# SWM330 register map
File version: 1.0
SWM330 Microcontroller registers
CPU: CM0 r1p0, little endian, 2 interrupt priority bits
Registers are 32-bit, read-write, no defined reset value unless marked. A register's access mark holds for its fields unless they carry their own. Offsets are from the block's base; lines under a group give offsets from that group; [hi:lo] are bit positions; {n}, {i} and the like mark numbered series; 'fields as' and 'values as' point back to an identical list; <NAME> marks a mode.

## Memory map
0x40000000 SYS size 0xA5840 — Registers group
0x40000800 DMA size 0x50 — Registers group
0x40001000 SDIO size 0x40 — Registers group
0x40001800 LCD size 0x10C — Registers group
0x40002000 CRC size 0x10 — Registers group
0x40002800 SRA size 0x48 — Registers group
0x40003000 DMA2D size 0x4C — Registers group
0x40003900 DVP size 0x58 — Registers group
0x40004000 JPEG size 0x400 — Registers group
0x40005000 RDMA size 0x1C — Registers group
0x40040000 GPIOA size 0x80 — Registers group
0x40040800 GPIOB size 0x80
0x40041000 GPIOC size 0x80
0x40041800 GPIOD size 0x80
0x40042000 SPI0 size 0x14 — Registers group
0x40042800 I2S0 size 0x18 — Registers group
0x40043000 DAC0 size 0x10 — Registers group
0x40043800 ADC0 size 0xA0 — Registers group
0x40044000 TIMR0 size 0x34 — Registers group
0x40044040 TIMR1 size 0x34
0x40044400 TIMRG size 0x44 — Registers group
0x40044800 BTIMR0 size 0x34
0x40044840 BTIMR1 size 0x34
0x40044880 BTIMR2 size 0x34
0x400448C0 BTIMR3 size 0x34
0x40044C00 BTIMRG size 0x44
0x40045000 PWM0 size 0x80 — Registers group
0x40045080 PWM1 size 0x80
0x40045400 PWMG size 0x28 — Registers group
0x40045800 FMC size 0x28 — Registers group
0x400A0000 PORTA size 0x70C — Registers group
0x400A0010 PORTB size 0x70C
0x400A0020 PORTC size 0x70C
0x400A0030 PORTD size 0x70C
0x400A0040 PORTE size 0x70C
0x400A0800 WDT size 0x14 — Registers group
0x400A1000 UART0 size 0x20 — Registers group
0x400A1800 UART1 size 0x20
0x400A2000 UART2 size 0x20
0x400A2800 UART3 size 0x20
0x400A3000 UART4 size 0x20
0x400A3800 RTC size 0xB0 — Registers group
0x400A4000 I2C0 size 0x38 — Registers group
0x400A4800 I2C1 size 0x38
0x400A5000 CAN0 size 0x3C0 — Registers group
0x400A6000 GPIOE size 0x80
0x78000000 QSPI0 size 0x48 — Registers group
0x78000800 QSPI1 size 0x48
0x88000000 PSRAMC size 0x28 — Registers group

## SYS — Registers group
Base 0x40000000
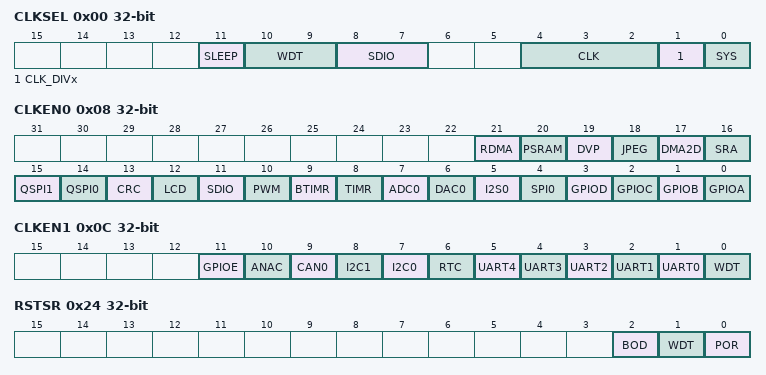
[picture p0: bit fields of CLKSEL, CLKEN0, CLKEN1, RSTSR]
0x00 CLKSEL
  [11] SLEEP, [10:9] WDT, [8:7] SDIO, [4:2] CLK, [1] CLK_DIVx, [0] SYS
0x04 CLKDIVx_ON
0x08 CLKEN0
  [21] RDMA, [20] PSRAM, [19] DVP, [18] JPEG, [17] DMA2D, [16] SRA, [15] QSPI1, [14] QSPI0, [13] CRC, [12] LCD, [11] SDIO, [10] PWM, [9] BTIMR, [8] TIMR, [7] ADC0, [6] DAC0, [5] I2S0, [4] SPI0, [3] GPIOD, [2] GPIOC, [1] GPIOB, [0] GPIOA
0x0C CLKEN1
  [11] GPIOE, [10] ANAC, [9] CAN0, [8] I2C1, [7] I2C0, [6] RTC, [n+1] UART{n} (n=0..4), [0] WDT
0x10 MODE
  [0] WKEDGE
0x24 RSTSR
  [2] BOD, [1] WDT, [0] POR
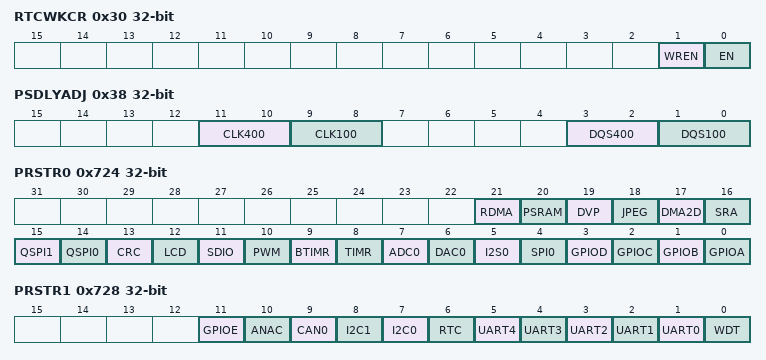
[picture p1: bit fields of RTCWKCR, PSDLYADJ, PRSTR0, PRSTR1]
0x30 RTCWKCR
  [1] WREN, [0] EN
0x34 RTCWKSR
  [0] FLAG
0x38 PSDLYADJ
  [11:10] CLK400, [9:8] CLK100, [3:2] DQS400, [1:0] DQS100
{0x80+4i} CHIPID[{i}] (i=0..3) ro
{0x90+4i} BACKUP[{i}] (i=0..5)
0x100 PAWKEN
0x104 PBWKEN
0x108 PCWKEN
0x10C PDWKEN
0x110 PEWKEN
0x130 PAWKSR
0x134 PBWKSR
0x138 PCWKSR
0x13C PDWKSR
0x140 PEWKSR
0x720 PRSTEN
0x724 PRSTR0
  fields as CLKEN0
0x728 PRSTR1
  fields as CLKEN1
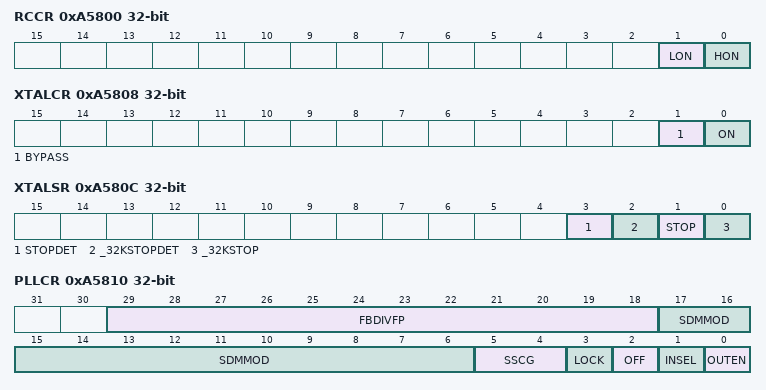
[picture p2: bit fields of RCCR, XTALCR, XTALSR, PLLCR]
0xA5800 RCCR
  [1] LON, [0] HON
0xA5808 XTALCR
  [1] BYPASS, [0] ON
0xA580C XTALSR
  [3] STOPDET, [2] _32KSTOPDET, [1] STOP, [0] _32KSTOP
0xA5810 PLLCR
  [29:18] FBDIVFP, [17:6] SDMMOD, [5:4] SSCG, [3] LOCK, [2] OFF, [1] INSEL, [0] OUTEN
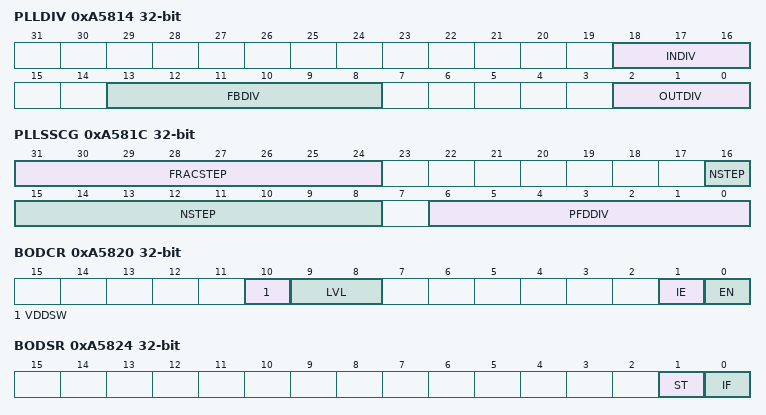
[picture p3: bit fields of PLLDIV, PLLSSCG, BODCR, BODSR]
0xA5814 PLLDIV
  [18:16] INDIV, [13:8] FBDIV, [2:0] OUTDIV
0xA581C PLLSSCG
  [31:24] FRACSTEP, [16:8] NSTEP, [6:0] PFDDIV
0xA5820 BODCR
  [10] VDDSW, [9:8] LVL, [1] IE, [0] EN
0xA5824 BODSR
  [1] ST, [0] IF
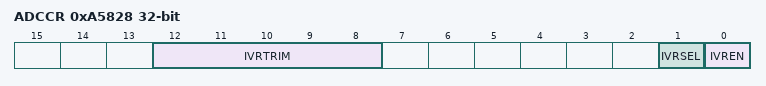
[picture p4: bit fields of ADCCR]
0xA5828 ADCCR
  [12:8] IVRTRIM, [1] IVRSEL, [0] IVREN
0xA582C PWRCR
0xA583C TEMPCR
  [0] EN

## PORTA — Registers group
Base 0x400A0000
Same registers: PORTB 0x400A0010, PORTC 0x400A0020, PORTD 0x400A0030, PORTE 0x400A0040
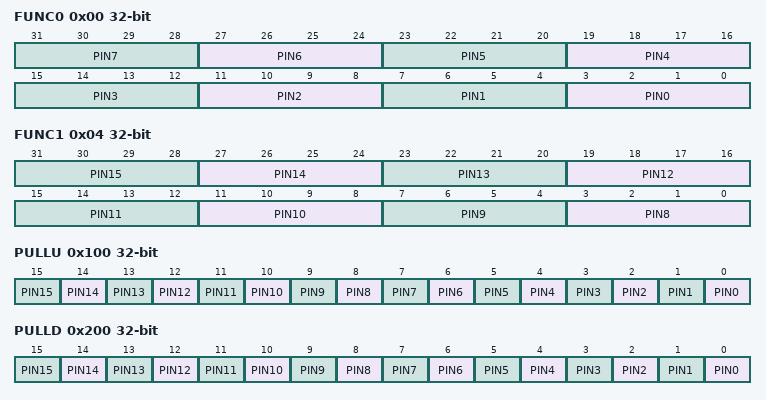
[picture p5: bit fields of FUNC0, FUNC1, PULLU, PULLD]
0x00 FUNC0
  [4n+3:4n] PIN{n} (n=0..7)
0x04 FUNC1
  [4n-29:4n-32] PIN{n} (n=8..15)
0x100 PULLU
  [n] PIN{n} (n=0..15)
0x200 PULLD
  [n] PIN{n} (n=0..15)
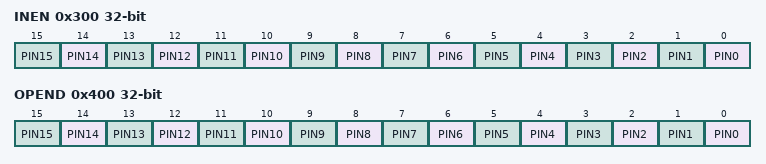
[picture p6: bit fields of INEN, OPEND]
0x300 INEN
  [n] PIN{n} (n=0..15)
0x400 OPEND
  [n] PIN{n} (n=0..15)
0x500 DRVS
0x600 SLEW
{0x700+4i} FUNMUX{i} (i=0..2)
